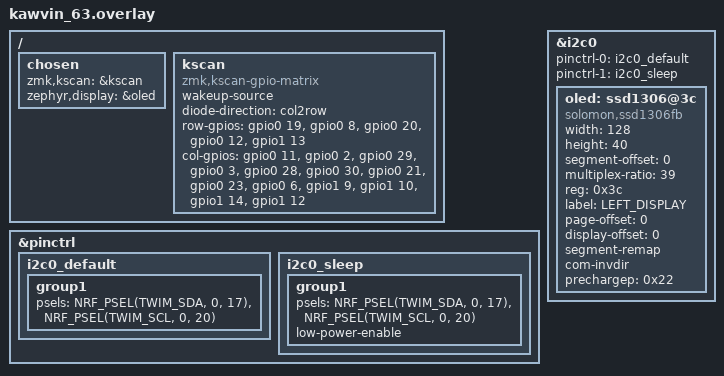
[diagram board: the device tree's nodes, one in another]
/*
 * Copyright (c) 2023 The ZMK Contributors
 *
 * SPDX-License-Identifier: MIT
 */

#include "kawvin_63.dtsi"
#include <dt-bindings/led/led.h>

&pinctrl {
    i2c0_default: i2c0_default {
        group1 {
            psels = <NRF_PSEL(TWIM_SDA, 0, 17)>,
                    <NRF_PSEL(TWIM_SCL, 0, 20)>;
        };
    };

    i2c0_sleep: i2c0_sleep {
        group1 {
            psels = <NRF_PSEL(TWIM_SDA, 0, 17)>,
                    <NRF_PSEL(TWIM_SCL, 0, 20)>;
            low-power-enable;
        };
    };
};

&i2c0 {
	status = "okay";
	//compatible = "nordic,nrf-twi";
	pinctrl-0 = <&i2c0_default>;
	pinctrl-1 = <&i2c0_sleep>;
	pinctrl-names = "default", "sleep";
    
	oled: ssd1306@3c {
        // OLED 0.42，使用以下
        width = <128>;  //72*40 
		height = <40>;  //72*40 
        compatible = "solomon,ssd1306fb";   //OLED 0.42
        segment-offset = <0>;   //OLED 0.42
        multiplex-ratio = <39>; //72*40  
        //com-sequential; //OLED 0.42注销本行
        
        // OLED 0.91或OLED 0.96，使用以下
        //width = <128>;
		//height = <64>;    //128*64
		//height = <32>;    //128*32
        //compatible = "solomon,ssd1306fb";   //OLED 0.91, OLED 0.96
        //segment-offset = <0>;   //OLED 0.91, OLED 0.96
        //multiplex-ratio = <31>; //128*32
        //multiplex-ratio = <63>; //128*64
        //com-sequential; //OLED 0.91或OLED 0.96 启用本行

        // OLED 1.30，使用以下
        //width = <128>;
		//height = <64>;
        //compatible = "sinowealth,sh1106";   //OLED 1.30
        //segment-offset = <2>;   //OLED 1.30
		//multiplex-ratio = <63>; //128*64
        //com-sequential; // OLED1.30注销本行

		reg = <0x3c>;
		label = "LEFT_DISPLAY";
		page-offset = <0>;
		display-offset = <0>;
		segment-remap;
		com-invdir;
        //inversion-on;   // 翻转颜色
		prechargep = <0x22>;
        
	};
};


/ {
    chosen {
        zmk,kscan = &kscan;
        zephyr,display = &oled;
    };

    kscan: kscan {
        compatible = "zmk,kscan-gpio-matrix";
        wakeup-source;

        diode-direction = "col2row";

        row-gpios
            = <&gpio0 19 (GPIO_PULL_DOWN | GPIO_ACTIVE_HIGH)>
            , <&gpio0  8 (GPIO_PULL_DOWN | GPIO_ACTIVE_HIGH)>
            , <&gpio0 20 (GPIO_PULL_DOWN | GPIO_ACTIVE_HIGH)>
            , <&gpio0 12 (GPIO_PULL_DOWN | GPIO_ACTIVE_HIGH)>
            , <&gpio1 13 (GPIO_PULL_DOWN | GPIO_ACTIVE_HIGH)>
            ;

        col-gpios
            = <&gpio0 11 GPIO_ACTIVE_HIGH>
            , <&gpio0  2 GPIO_ACTIVE_HIGH>
            , <&gpio0 29 GPIO_ACTIVE_HIGH>
            , <&gpio0  3 GPIO_ACTIVE_HIGH>
            , <&gpio0 28 GPIO_ACTIVE_HIGH>
            , <&gpio0 30 GPIO_ACTIVE_HIGH>
            , <&gpio0 21 GPIO_ACTIVE_HIGH>
            , <&gpio0 23 GPIO_ACTIVE_HIGH>
            , <&gpio0  6 GPIO_ACTIVE_HIGH>
            , <&gpio1  9 GPIO_ACTIVE_HIGH>
            , <&gpio1 10 GPIO_ACTIVE_HIGH>
            , <&gpio1 14 GPIO_ACTIVE_HIGH>
            , <&gpio1 12 GPIO_ACTIVE_HIGH>
            ;
    };
};


